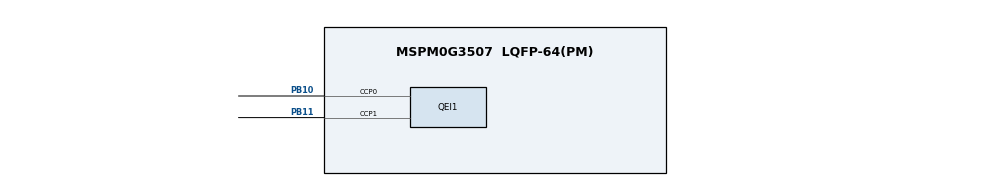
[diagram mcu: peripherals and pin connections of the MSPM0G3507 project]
/**
 * These arguments were used when this file was generated. They will be automatically applied on subsequent loads
 * via the GUI or CLI. Run CLI with '--help' for additional information on how to override these arguments.
 * @cliArgs --device "MSPM0G350X" --part "Default" --package "LQFP-64(PM)" --product "mspm0_sdk@2.10.00.04"
 * @v2CliArgs --device "MSPM0G3507" --package "LQFP-64(PM)" --product "mspm0_sdk@2.10.00.04"
 * @versions {"tool":"1.26.2+4477"}
 */

/**
 * Import the modules used in this configuration.
 */
const GPIO   = scripting.addModule("/ti/driverlib/GPIO", {}, false);
const GPIO1  = GPIO.addInstance();
const GPIO2  = GPIO.addInstance();
const GPIO3  = GPIO.addInstance();
const GPIO4  = GPIO.addInstance();
const GPIO5  = GPIO.addInstance();
const GPIO6  = GPIO.addInstance();
const GPIO7  = GPIO.addInstance();
const GPIO8  = GPIO.addInstance();
const GPIO9  = GPIO.addInstance();
const GPIO10 = GPIO.addInstance();
const PWM    = scripting.addModule("/ti/driverlib/PWM", {}, false);
const PWM1   = PWM.addInstance();
const QEI    = scripting.addModule("/ti/driverlib/QEI", {}, false);
const QEI1   = QEI.addInstance();
const SYSCTL = scripting.addModule("/ti/driverlib/SYSCTL");
const TIMER  = scripting.addModule("/ti/driverlib/TIMER", {}, false);
const TIMER1 = TIMER.addInstance();

/**
 * Write custom configuration values to the imported modules.
 */
GPIO1.$name                          = "GPIO_GRP_0";
GPIO1.associatedPins[0].$name        = "AN1";
GPIO1.associatedPins[0].assignedPort = "PORTB";
GPIO1.associatedPins[0].assignedPin  = "1";

const Board = scripting.addModule("/ti/driverlib/Board", {}, false);

GPIO2.$name                          = "GPIO_GRP_1";
GPIO2.associatedPins[0].$name        = "AN2";
GPIO2.associatedPins[0].assignedPort = "PORTB";
GPIO2.associatedPins[0].assignedPin  = "2";

GPIO3.$name                          = "GPIO_GRP_2";
GPIO3.associatedPins[0].$name        = "BN1";
GPIO3.associatedPins[0].assignedPort = "PORTB";
GPIO3.associatedPins[0].assignedPin  = "3";

GPIO4.$name                          = "GPIO_GRP_3";
GPIO4.associatedPins[0].assignedPin  = "4";
GPIO4.associatedPins[0].assignedPort = "PORTB";
GPIO4.associatedPins[0].$name        = "BIN2";

GPIO5.$name                          = "GPIO_GRP_4";
GPIO5.associatedPins[0].$name        = "STAYBY";
GPIO5.associatedPins[0].assignedPort = "PORTB";
GPIO5.associatedPins[0].assignedPin  = "0";

GPIO6.$name                              = "GPIO_GRP_6";
GPIO6.associatedPins[0].$name            = "AA";
GPIO6.associatedPins[0].direction        = "INPUT";
GPIO6.associatedPins[0].interruptEn      = true;
GPIO6.associatedPins[0].assignedPort     = "PORTA";
GPIO6.associatedPins[0].assignedPin      = "17";
GPIO6.associatedPins[0].internalResistor = "PULL_UP";
GPIO6.associatedPins[0].polarity         = "FALL";

GPIO7.$name                              = "GPIO_GRP_7";
GPIO7.associatedPins[0].$name            = "AB";
GPIO7.associatedPins[0].direction        = "INPUT";
GPIO7.associatedPins[0].assignedPort     = "PORTA";
GPIO7.associatedPins[0].assignedPin      = "18";
GPIO7.associatedPins[0].internalResistor = "PULL_UP";

GPIO8.$name                              = "GPIO_GRP_8";
GPIO8.associatedPins[0].$name            = "AA2";
GPIO8.associatedPins[0].direction        = "INPUT";
GPIO8.associatedPins[0].assignedPort     = "PORTA";
GPIO8.associatedPins[0].assignedPin      = "26";
GPIO8.associatedPins[0].interruptEn      = true;
GPIO8.associatedPins[0].polarity         = "FALL";
GPIO8.associatedPins[0].internalResistor = "PULL_UP";

GPIO9.$name                              = "GPIO_GRP_9";
GPIO9.associatedPins[0].$name            = "AB2";
GPIO9.associatedPins[0].direction        = "INPUT";
GPIO9.associatedPins[0].assignedPort     = "PORTA";
GPIO9.associatedPins[0].assignedPin      = "27";
GPIO9.associatedPins[0].internalResistor = "PULL_UP";

GPIO10.$name                          = "TEST";
GPIO10.associatedPins[0].$name        = "PIN_0";
GPIO10.associatedPins[0].assignedPort = "PORTB";
GPIO10.associatedPins[0].assignedPin  = "6";

PWM1.$name               = "PWM_0";
PWM1.timerCount          = 3200;
PWM1.pwmMode             = "EDGE_ALIGN_UP";
PWM1.peripheral.$assign  = "TIMG0";
PWM1.PWM_CHANNEL_0.$name = "ti_driverlib_pwm_PWMTimerCC0";
PWM1.PWM_CHANNEL_1.$name = "ti_driverlib_pwm_PWMTimerCC1";
PWM1.ccp0PinConfig.$name = "ti_driverlib_gpio_GPIOPinGeneric0";
PWM1.ccp1PinConfig.$name = "ti_driverlib_gpio_GPIOPinGeneric1";

QEI1.$name                          = "QEI_0";
QEI1.enableIndexInput               = true;
QEI1.enableHallInput                = true;
QEI1.ccp0PinConfig.$name            = "ti_driverlib_gpio_GPIOPinGeneric4";
QEI1.ccp0PinConfig.enableConfig     = true;
QEI1.ccp0PinConfig.internalResistor = "PULL_UP";
QEI1.ccp1PinConfig.$name            = "ti_driverlib_gpio_GPIOPinGeneric5";
QEI1.ccp1PinConfig.enableConfig     = true;
QEI1.ccp1PinConfig.internalResistor = "PULL_UP";
QEI1.peripheral.$assign             = "TIMG8";
QEI1.peripheral.ccp0Pin.$assign     = "PB10";
QEI1.peripheral.ccp1Pin.$assign     = "PB11";
QEI1.idxPinConfig.$name             = "ti_driverlib_gpio_GPIOPinGeneric2";

SYSCTL.forceDefaultClkConfig = true;

TIMER1.$name              = "TIMER_1";
TIMER1.timerPeriod        = "10 ms";
TIMER1.timerMode          = "PERIODIC";
TIMER1.timerClkPrescale   = 32;
TIMER1.interrupts         = ["LOAD"];
TIMER1.interruptPriority  = "0";
TIMER1.peripheral.$assign = "TIMG6";

/**
 * Pinmux solution for unlocked pins/peripherals. This ensures that minor changes to the automatic solver in a future
 * version of the tool will not impact the pinmux you originally saw.  These lines can be completely deleted in order to
 * re-solve from scratch.
 */
GPIO1.associatedPins[0].pin.$suggestSolution  = "PB1";
Board.peripheral.$suggestSolution             = "DEBUGSS";
Board.peripheral.swclkPin.$suggestSolution    = "PA20";
Board.peripheral.swdioPin.$suggestSolution    = "PA19";
GPIO2.associatedPins[0].pin.$suggestSolution  = "PB2";
GPIO3.associatedPins[0].pin.$suggestSolution  = "PB3";
GPIO4.associatedPins[0].pin.$suggestSolution  = "PB4";
GPIO5.associatedPins[0].pin.$suggestSolution  = "PB0";
GPIO6.associatedPins[0].pin.$suggestSolution  = "PA17";
GPIO7.associatedPins[0].pin.$suggestSolution  = "PA18";
GPIO8.associatedPins[0].pin.$suggestSolution  = "PA26";
GPIO9.associatedPins[0].pin.$suggestSolution  = "PA27";
GPIO10.associatedPins[0].pin.$suggestSolution = "PB6";
PWM1.peripheral.ccp0Pin.$suggestSolution      = "PA12";
PWM1.peripheral.ccp1Pin.$suggestSolution      = "PA13";
QEI1.peripheral.idxPin.$suggestSolution       = "PA1";
SYSCTL.peripheral.$suggestSolution            = "SYSCTL";
